# RZT2M register map
Vendor: Renesas Electronics Corporation; Series: RZT; File version: 1.20.01
CPU: other r0p0, little endian, MPU, no FPU, VTOR, 4 interrupt priority bits, 624 interrupts
Registers are 32-bit, read-write, reset 0x0 unless marked. A register's access mark holds for its fields unless they carry their own. Offsets are from the block's base; [hi:lo] are bit positions; {n}, {i} and the like mark numbered series.

## ETHSW (part 2 of 3) — Ethernet Switch
Base 0x80120000
0x5C8 TS_FIFO_READ_TIMESTAMP ro — 32-bit Timestamp Value Read from FIFO
  [31:0] TIMESTAMP — 32-bit timestamp value read from the FIFO
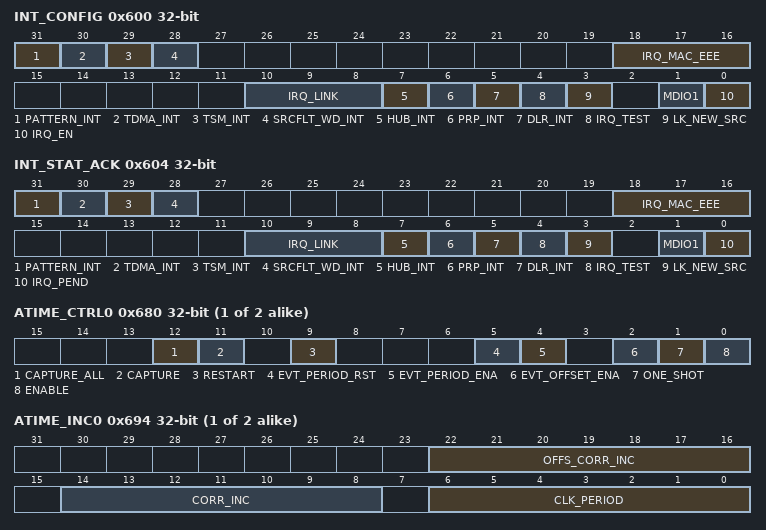
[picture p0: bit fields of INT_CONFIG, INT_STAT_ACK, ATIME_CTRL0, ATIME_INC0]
0x600 INT_CONFIG — Interrupt Enable Configuration Register
  [31] PATTERN_INT — Enable Interrupt for RX Pattern Matcher
  [30] TDMA_INT — Enable Interrupt for TDMA scheduler
  [29] TSM_INT — Enable Interrupt for TSM (Timer, Timestamping)
  [28] SRCFLT_WD_INT — MAC Address Source Filtering Watchdog
  [18:16] IRQ_MAC_EEE — Per Line Port MAC interrupt
  [10:8] IRQ_LINK — Per Line Port Phy Link Change Interrupt Enable
  [7] HUB_INT — Enable Interrupt for HUB
  [6] PRP_INT — Enable Interrupt for PRP
  [5] DLR_INT — Enable Interrupt for DLR
  [4] IRQ_TEST — When set, an interrupt is triggered immediately. Can be used to cause a software controlled interrupt for testing purposes.
  [3] LK_NEW_SRC — Enable Interrupt for New Source Address
  [1] MDIO1 — Enable Interrupt on Transaction Complete from MDIO Controller
  [0] IRQ_EN — Interrupt Global Enable
0x604 INT_STAT_ACK — Interrupt Status/ACK Register
  [31] PATTERN_INT ro — Interrupt Pending Status from RX Pattern Matcher Module
  [30] TDMA_INT ro — Interrupt Pending Status from TDMA Scheduler
  [29] TSM_INT ro — Interrupt Pending Interrupt Indication from TSM (Timestamping) module
  [28] SRCFLT_WD_INT — Interrupt Pending Status for MAC Source Filtering Watchdog
  [18:16] IRQ_MAC_EEE — Interrupt Pending Status per Line Port MAC Interrupt
  [10:8] IRQ_LINK — Interrupt Pending per Line Port Phy Link Change Interrupt
  [7] HUB_INT ro — Interrupt Pending Status from Hub Module
  [6] PRP_INT ro — Interrupt Pending Status from PRP Module
  [5] DLR_INT ro — Interrupt Pending Status from DLR Module
  [4] IRQ_TEST ro — Interrupt Status for IRQ_TEST
  [3] LK_NEW_SRC — Latched Interrupt Status for LK_NEW_SRC
  [1] MDIO1 — Latched Interrupt Status for MDIO1
  [0] IRQ_PEND ro — Interrupt Pending Status
{0x680+0x20*i} ATIME_CTRL{i} (i=0..1) — Timer {i} Control Register (n = 0, 1)
  [12] CAPTURE_ALL — Capture All Timers Value (Command Bit)
  [11] CAPTURE — Capture Time Value (Command Bit)
  [9] RESTART — Resets the Timer to Zero (Command Bit)
  [5] EVT_PERIOD_RST — Reset Timer on Periodical Event
  [4] EVT_PERIOD_ENA — Enable Periodical Event
  [2] EVT_OFFSET_ENA — Enable Offset Event
  [1] ONE_SHOT — Avoid timer wrap around. If set, the timer stops at maximum. An overflow interrupt (TSM_CONFIG.IRQ_ATIME_OVER) occurs (if enabled) when the maximum is reached.
  [0] ENABLE
{0x684+0x20*i} ATIME{i} (i=0..1) — Timer {i} Count Register (n = 0, 1)
  [31:0] TIMER_VAL — Timer Value
{0x688+0x20*i} ATIME_OFFSET{i} (i=0..1) — Timer {i} Offset Register (n = 0, 1)
  [31:0] OFFSET — Value used for performing offset corrections without changing the drift correction
{0x68C+0x20*i} ATIME_EVT_PERIOD{i} (i=0..1) reset 0x3B9ACA00 — Timer {i} Periodic Event Register (n = 0, 1)
  [31:0] PERIOD — Value for generating periodic events
{0x690+0x20*i} ATIME_CORR{i} (i=0..1) — Timer {i} Correction Period Register (n = 0, 1)
  [30:0] CORR_PERIOD — Correction Period
{0x694+0x20*i} ATIME_INC{i} (i=0..1) — Timer {i} Increment Register (n = 0, 1)
  [22:16] OFFS_CORR_INC — Offset Correction Increment Value
  [14:8] CORR_INC — Correction Increment Value
  [6:0] CLK_PERIOD — Clock Period of the Timestamping Clock (125 MHz) in nanoseconds
{0x698+0x20*i} ATIME_SEC{i} (i=0..1) — Timer {i} Seconds Time Register (n = 0, 1)
  [31:0] SEC_TIME — Seconds Time Value
{0x69C+0x20*i} ATIME_OFFS_CORR{i} (i=0..1) — Timer {i} Offset Correction Counter Register (n = 0, 1)
  [31:0] OFFS_CORR_CNT — Offset Correction Counter
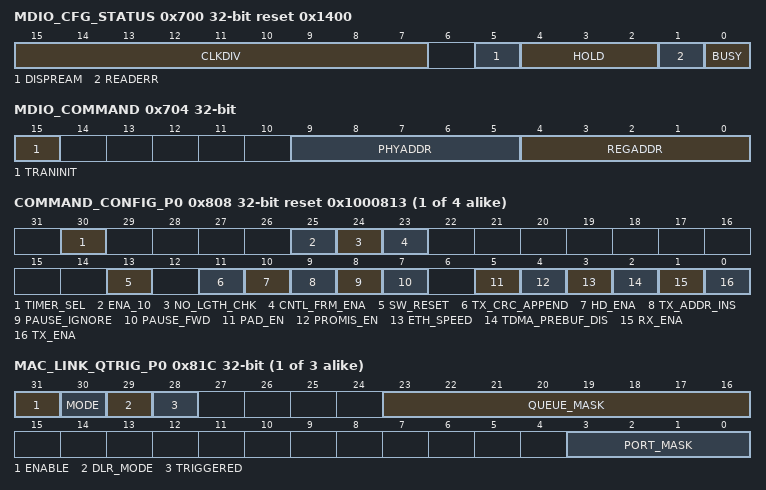
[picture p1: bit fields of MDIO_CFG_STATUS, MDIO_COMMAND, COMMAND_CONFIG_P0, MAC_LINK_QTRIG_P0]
0x700 MDIO_CFG_STATUS reset 0x1400 — MDIO Configuration and Status Register
  [15:7] CLKDIV — MDIO Clock Divisor
  [5] DISPREAM — Disable Preamble
    0=Enable Preamble; 1=Disable Preamble
  [4:2] HOLD — MDIO Hold Time Setting
    0=1 PCLKM clock cycle (default); 1=3 PCLKM clock cycles; 2=5 PCLKM clock cycles; 3=7 PCLKM clock cycles; 4=9 PCLKM clock cycles; 5=11 PCLKM clock cycles; 6=13 PCLKM clock cycles; 7=15 PCLKM clock cycles
  [1] READERR ro — MDIO Read Error
  [0] BUSY ro — MDIO Busy
0x704 MDIO_COMMAND — MDIO PHY Command Register
  [15] TRANINIT — If set to 1, a read transaction is initiated.
  [9:5] PHYADDR — PHY Address
  [4:0] REGADDR — Register Address
0x708 MDIO_DATA
  [15:0] MDIO_DATA
{0x800+0x400*i} REV_P{i} (i=0..3) ro reset 0x10002 (reset mask 0xFFFFFFFA) — Port {i} MAC Core Revision (n = 0 to 3)
  [31:0] REV — MAC Core Revision
{0x808+0x400*i} COMMAND_CONFIG_P{i} (i=0..3) reset 0x1000813 — Port {i} Command Configuration Register (n = 0 to 3)
  [30] TIMER_SEL — Selects the default timer to use for timestamping operations on transmit and on receive. The value is used when not overridden by the PTP auto-response function, pattern matchers or force forwarding information in a management tag.
    0=Use timer 0; 1=Use timer 1
  [25] ENA_10 — This bit has no effect except PHYSPEED bit of STATUS_Pn register.
  [24] NO_LGTH_CHK — Payload Length Check Disable
  [23] CNTL_FRM_ENA — MAC Control Frame Enable
  [13] SW_RESET — Self Clearing Reset Command Bit
  [11] TX_CRC_APPEND — Enable CRC Append on Transmit
  [10] HD_ENA — Enable auto full/half-duplex operation (set to 1) or full-duplex only (set to 0).
  [9] TX_ADDR_INS ro — Non writable bit, fixed to 0 always.
  [8] PAUSE_IGNORE — Ignore Pause Frame Quanta
  [7] PAUSE_FWD ro — Terminate/Forward Pause Frames
  [5] PAD_EN ro — Enable/Disable Frame Padding Remove on Receive
  [4] PROMIS_EN ro — Enable/Disable MAC Promiscuous Operation
  [3] ETH_SPEED — Operation Mode Definition
    0=10/100 Megabit mode; 1=1 Gigabit mode
  [2] TDMA_PREBUF_DIS — When set to 1, the MAC does not request a new frame from the IMC until the current frame is completed. This can cause the IPG between frames to be more than the value in TX_IPG_LENGTH.
  [1] RX_ENA — Enable/Disable MAC Receive Path
  [0] TX_ENA — Enable/Disable MAC Transmit Path
{0x80C+0x400*i} MAC_ADDR_0_P{i} (i=0..2) — Port {i} MAC Address Register 0 (n = 0 to 2)
  [31:0] MAC_ADDR — The first 4 bytes of the MAC address of the port. First byte is bits [7:0]. The MAC address is used on locally generated frames such as pause frames, peer-delay response.
{0x810+0x400*i} MAC_ADDR_1_P{i} (i=0..2) — Port {i} MAC Address Register 1 (n = 0 to 2)
  [15:0] MAC_ADDR — The last 2 bytes of the MAC address of the port. Bits [7:0] is the 5th byte and bits [15:8] is the 6th byte.
{0x814+0x400*i} FRM_LENGTH_P{i} (i=0..3) reset 0x5FE — Port {i} Maximum Frame Length Register (n = 0 to 3)
  [13:0] FRM_LENGTH — Maximum Frame Length
{0x818+0x400*i} PAUSE_QUANT_P{i} (i=0..3) ro reset 0xFFFF — Port {i} MAC Pause Quanta (n = 0 to 3)
  [15:0] PAUSE_QUANT — Pause Quanta
{0x81C+0x400*i} MAC_LINK_QTRIG_P{i} (i=0..2) — Port {i} Trigger Event Configuration Register (n = 0 to 2)
  [31] ENABLE — Write to 1 to enable the Link Queue Trigger feature. When the link status (phy_link) transitions from 1 -> 0, a trigger event is generated to the memory controller for the ports and queues indicated in PORT_MASK and QUEUE_MASK.
  [30] MODE — When set to 0, only a single Link_Status frame is generated. This is to prevent sending multiple frames due to link flapping.
  [29] DLR_MODE — When set to 0, the DLR state machine is ignored. When set to 1, the Link Queue Trigger occurs only if the DLR state machine is in the NORMAL or FAULT state.
  [28] TRIGGERED — When MODE is set to 1, TRIGGERED indicates whether a frame was transmitted. When MODE is set to 0, TRIGGERED is always 0. This flag clears when the register is written.
  [23:16] QUEUE_MASK — 1-bit per queue indicating from which queues a frame is transmitted from the ports indicated by PORT_MASK. A single frame is transmitted per indicated port in PORT_MASK among the queues indicated by QUEUE_MASK.
  [3:0] PORT_MASK — Per-port Bit Mask
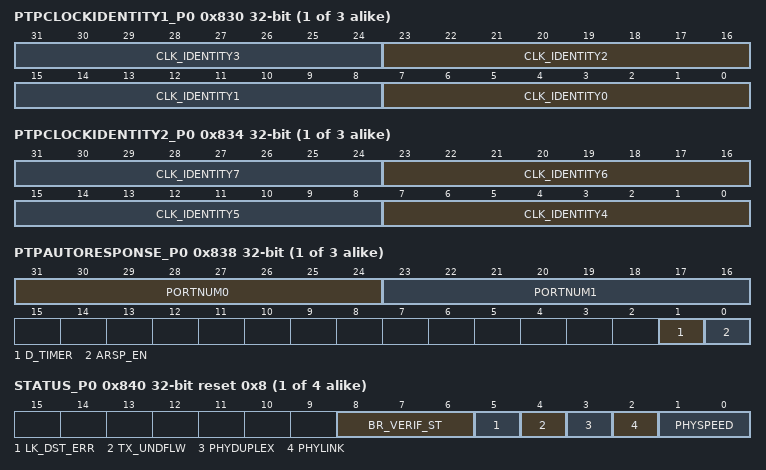
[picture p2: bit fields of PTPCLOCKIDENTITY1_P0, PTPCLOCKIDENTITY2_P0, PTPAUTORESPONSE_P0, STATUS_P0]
{0x830+0x400*i} PTPCLOCKIDENTITY1_P{i} (i=0..2) — Port {i} PTP Clock Identity 1 Register (n = 0 to 2)
  [8n+7:8n] CLK_IDENTITY{n} (n=0..3) — {n+20}, portIdentity.ClockIdentity[{n}]
{0x834+0x400*i} PTPCLOCKIDENTITY2_P{i} (i=0..2) — Port {i} PTP Clock Identity 2 Register (n = 0 to 2)
  [8n-25:8n-32] CLK_IDENTITY{n} (n=4..7) — {n+20}, portIdentity.ClockIdentity[{n}]
{0x838+0x400*i} PTPAUTORESPONSE_P{i} (i=0..2) — Port {i} PTP Auto Response Register (n = 0 to 2)
  [31:24] PORTNUM0 — 28, portIdentity.PortNumber[0] (msb)
  [23:16] PORTNUM1 — 29, portIdentity.PortNumber[1] (lsb)
  [1] D_TIMER — Default timer to use for auto-response generation
    0=Use timer 0; 1=Use timer 1
  [0] ARSP_EN — Auto Response Enable
{0x840+0x400*i} STATUS_P{i} (i=0..3) reset 0x8 (reset mask 0x1FC) — Port {i} Status Register
  [8:6] BR_VERIF_ST ro — Indicates the current status of the verification according to clause 30.14.1.2 of the 802.3br specification
    0=Unknown (during reset); 1=Initial (when preemption is disabled); 2=Verifying; 3=Succeeded; 4=Failed; 5=Disabled (if preempt verification is disabled)
  [5] LK_DST_ERR — Indicates that the L2 destination lookup process failed to complete in time before the next frame was received at the port. This should never occur under normal operation. The cause could be from IPG violations in the received frames.
  [4] TX_UNDFLW — Indicates that the transmit MAC underflow. This shall never occur during normal operation.
  [3] PHYDUPLEX ro — Duplex status from PHY interface
    0=half-duplex; 1=full-duplex
  [2] PHYLINK ro — Link status from PHY interface
    0=link down; 1=link up
  [1:0] PHYSPEED ro — Currently Active PHY Interface Speed
    0=10 Mbps; 1=100 Mbps; 2=1 Gbps
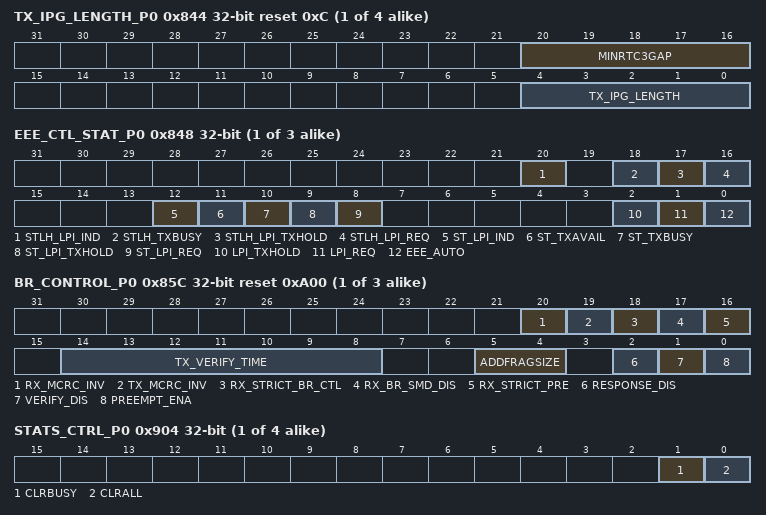
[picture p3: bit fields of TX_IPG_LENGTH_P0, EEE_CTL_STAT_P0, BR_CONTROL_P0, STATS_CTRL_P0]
{0x844+0x400*i} TX_IPG_LENGTH_P{i} (i=0..3) reset 0xC (reset mask 0x11001F) — Port {i} Transmit IPG Length Register (n = 0 to 3)
  [20:16] MINRTC3GAP
  [4:0] TX_IPG_LENGTH — Define transmit interpacket gap in octets. Allowed values are in the range of 8 to 31.
{0x848+0x400*i} EEE_CTL_STAT_P{i} (i=0..2) — Port {i} MAC EEE Functions Control and Status (n = 0 to 2)
  [20] STLH_LPI_IND ro — Status (latched high) of Received LPI (ST_LPI_IND)
  [18] STLH_TXBUSY ro — Status (latched high) if the MAC is/was Transmitting
  [17] STLH_LPI_TXHOLD ro — Status (latched high) of Internal LPI_TXHOLD to the MAC
  [16] STLH_LPI_REQ ro — Status (latched high) of Internal LPI_REQ to the MAC
  [12] ST_LPI_IND ro — Status (real time) of Received LPI
  [11] ST_TXAVAIL ro — Status (real time) if the MAC transmit FIFO has data available for transmission.
  [10] ST_TXBUSY ro — Status (real time) if the MAC is currently transmitting.
  [9] ST_LPI_TXHOLD ro — Status (real time) of Internal LPI_TXHOLD to the MAC
  [8] ST_LPI_REQ ro — Status (real time) of Internal LPI_REQ to the MAC
  [2] LPI_TXHOLD — MAC Transmission Hold
  [1] LPI_REQ — Request LPI Transmission when MAC Becomes Idle
  [0] EEE_AUTO — EEE Automatic Mode of Operation
{0x84C+0x400*i} EEE_IDLE_TIME_P{i} (i=0..2) — Port {i} EEE Idle Time Register (n = 0 to 2)
  [31:0] EEE_IDLE_TIME — Time (-1) the transmitter must be idle before transmission of LPI begins. A 32-bit value in steps of 32 switch operating clock cycles. A value of 0 disables the timer. The value must be set to 1 less count.
{0x850+0x400*i} EEE_TWSYS_TIME_P{i} (i=0..2) — Port {i} EEE Wake Up Time Register (n = 0 to 2)
  [31:0] EEE_WKUP_TIME — Time (-1) after PHY wakeup until the MAC is allowed to begin transmitting the first frame again. A 32-bit value in steps of switch operating clock cycles. A value of 0 disables the timer. The value must be set to 1 less count.
{0x854+0x400*i} IDLE_SLOPE_P{i} (i=0..3) — Port {i} MAC Traffic Shaper Bandwidth Control
  [10:0] IDLE_SLOPE — Traffic Shaper Bandwidth Control
{0x858+0x400*i} CT_DELAY_P{i} (i=0..2) — Port {i} Cut-Through Delay Indication Register
  [8:0] CT_DELAY — Delay Value in 400 ns / 40 ns / 8 ns increments (frequency of the MII PHY interface)
{0x85C+0x400*i} BR_CONTROL_P{i} (i=0..2) reset 0xA00 — Port {i} 802.3br Frame Configuration Register
  [20] RX_MCRC_INV — When set to 1, the 32-bit XOR mask used to calculate the mCRC for received frames is inverted. This bit must always be written to 0 and only used for debugging.
  [19] TX_MCRC_INV — When set to 1, the 32-bit XOR mask used to calculate the mCRC for transmitted frames is inverted. This bit must always be written to 0 and only used for debugging.
  [18] RX_STRICT_BR_CTL — When set to 1, strict checking of VERIFY and RESPONSE frames is enabled. When set to 1, the frame contents and frame length checks are also performed on these frames. The mCRC is always checked regardless of the value of this register. This bit must be set to 0 to be compliant with the functionality described in IEEE 802.3br.
  [17] RX_BR_SMD_DIS — When set to 1, the receiver does not decode the 802.3br SMDs and assumes all frames are express frames. This bit must be set to 0 for correct operation with 802.3br, and can be set to 1 when 802.3br is not enabled to avoid false detection of SMDs.
  [16] RX_STRICT_PRE — When set to 1, the preamble is checked so all bytes except the SFD are 0x55. When set to 0, only the last 2 bytes of the preamble are checked (SFD/SMD and FRAG_COUNT). It is recommended to set this bit to 1 to comply with the 802.3br specification. This bit must be set to 0 if only non-802.3br traffic is expected (for example, normal Ethernet traffic) and if custom preamble is used.
  [14:8] TX_VERIFY_TIME — Preemption verification timeout in milliseconds.
  [5:4] ADDFRAGSIZE — Minimum fragment size in increments of 64 bytes.
  [2] RESPONSE_DIS — When set to 1 prevents the MAC from responding to "verify" frames.
  [1] VERIFY_DIS — When set to 1, disables the verify process required for preemption operation.
  [0] PREEMPT_ENA — When set to 1, enables 802.3br Frame Preemption.
{0x868+0x400*i} AFRAMESTRANSMITTEDOK_P{i} (i=0..3) ro — Port {i} MAC Transmitted Valid Frame Count Register (n = 0 to 3)
  [31:0] TXVALIDCOUNT — PORT n, this field indicates the number of MAC Valid Transmitted, including pause.
{0x86C+0x400*i} AFRAMESRECEIVEDOK_P{i} (i=0..3) ro — Port {i} MAC Received Valid Frame Count Register (n = 0 to 3)
  [31:0] RXVALIDCOUNT — PORT n, this field indicates the number of MAC Valid Received, including pause.
{0x870+0x400*i} AFRAMECHECKSEQUENCEERRORS_P{i} (i=0..3) ro — Port {i} MAC FCS Error Frame Count Register (n = 0 to 3)
  [31:0] FCSERRCOUNT — PORT n, this field indicates the number of MAC Valid Length but CRC error.
{0x874+0x400*i} AALIGNMENTERRORS_P{i} (i=0..3) ro — Port {i} MAC Alignment Error Frame Count Register (n = 0 to 3)
  [31:0] ALGNERRCOUNT — PORT n, this field indicates the number of MAC Odd Number of Nibbles (MII) Received.
{0x878+0x400*i} AOCTETSTRANSMITTEDOK_P{i} (i=0..3) ro — Port {i} MAC Transmitted Valid Frame Octets Register (n = 0 to 3)
  [31:0] TXVALIDOCTETS — PORT n, this field indicates the octets (the payload only) of MAC Valid Transmitted.
{0x87C+0x400*i} AOCTETSRECEIVEDOK_P{i} (i=0..3) ro — Port {i} MAC Received Valid Frame Octets Register (n = 0 to 3)
  [31:0] RXVALIDOCTETS — PORT n, this field indicates the octets (the payload only) of MAC Valid Received.
{0x880+0x400*i} ATXPAUSEMACCTRLFRAMES_P{i} (i=0..3) ro — Port {i} MAC Transmitted Pause Frame Count Register (n = 0 to 3)
  [31:0] TXPAUSECOUNT — PORT n, this field indicates the number of MAC Valid Pause Transmitted.
{0x884+0x400*i} ARXPAUSEMACCTRLFRAMES_P{i} (i=0..3) ro — Port {i} MAC Received Pause Frame Count Register (n = 0 to 3)
  [31:0] RXPAUSECOUNT — PORT n, this field indicates the number of MAC Valid Pause Received.
{0x888+0x400*i} IFINERRORS_P{i} (i=0..3) ro — Port {i} MAC Input Error Count Register (n = 0 to 3)
  [31:0] INERRCOUNT — PORT n, this field indicates the number of MAC Any Error During Reception such as CRC, Length, PHY Error, RX FIFO Overflow.
{0x88C+0x400*i} IFOUTERRORS_P{i} (i=0..3) ro — Port {i} MAC Output Error Count Register (n = 0 to 3)
  [31:0] OUTERRCOUNT — PORT n, this field indicates the number of MAC Frame Transmitted with PHY error.
{0x890+0x400*i} IFINUCASTPKTS_P{i} (i=0..3) ro — Port {i} MAC Received Unicast Frame Count Register (n = 0 to 3)
  [31:0] RXUCASTCOUNT — PORT n, this field indicates the number of MAC Unicast Frame Valid Received.
{0x894+0x400*i} IFINMULTICASTPKTS_P{i} (i=0..3) ro — Port {i} MAC Received Multicast Frame Count Register (n = 0 to 3)
  [31:0] RXMCASTCOUNT — PORT n, this field indicates the number of MAC Multicast Frame Valid Received.
{0x898+0x400*i} IFINBROADCASTPKTS_P{i} (i=0..3) ro — Port {i} MAC Received Broadcast Frame Count Register (n = 0 to 3)
  [31:0] RXBCASTCOUNT — PORT n, this field indicates the number of MAC Broadcast Frame Valid Received.
{0x89C+0x400*i} IFOUTDISCARDS_P{i} (i=0..3) ro — Port {i} MAC Discarded Outbound Frame Count Register (n = 0 to 3)
  [31:0] DISCOBCOUNT — Not Applicable
{0x8A0+0x400*i} IFOUTUCASTPKTS_P{i} (i=0..3) ro — Port {i} MAC Transmitted Unicast Frame Count Register (n = 0 to 3)
  [31:0] TXUCASTCOUNT — PORT n, this field indicates the number of MAC Unicast Frame Valid Transmitted.
{0x8A4+0x400*i} IFOUTMULTICASTPKTS_P{i} (i=0..3) ro — Port {i} MAC Transmitted Multicast Frame Count Register (n = 0 to 3)
  [31:0] TXMCASTCOUNT — PORT n, this field indicates the number of MAC Multicast Frame Valid Transmitted.
{0x8A8+0x400*i} IFOUTBROADCASTPKTS_P{i} (i=0..3) ro — Port {i} MAC Transmitted Broadcast Frame Count Register (n = 0 to 3)
  [31:0] TXBCASTCOUNT — PORT n, this field indicates the number of MAC Broadcast Frame Valid Transmitted.
{0x8AC+0x400*i} ETHERSTATSDROPEVENTS_P{i} (i=0..3) ro — Port {i} MAC Dropped Frame Count Register (n = 0 to 3)
  [31:0] DROPCOUNT — PORT n, this field indicates the number of MAC RX FIFO Full at frame start.
{0x8B0+0x400*i} ETHERSTATSOCTETS_P{i} (i=0..3) ro — Port {i} MAC All Frame Octets Register (n = 0 to 3)
  [31:0] ALLOCTETS
{0x8B4+0x400*i} ETHERSTATSPKTS_P{i} (i=0..3) ro — Port {i} MAC All Frame Count Register (n = 0 to 3)
  [31:0] ALLCOUNT
{0x8B8+0x400*i} ETHERSTATSUNDERSIZEPKTS_P{i} (i=0..3) ro — Port {i} MAC Too Short Frame Count Register (n = 0 to 3)
  [31:0] TOOSHRTCOUNT — PORT n, this field indicates the number of MAC too Short, Good CRC.
{0x8BC+0x400*i} ETHERSTATSOVERSIZEPKTS_P{i} (i=0..3) ro — Port {i} MAC Too Long Frame Count Register (n = 0 to 3)
  [31:0] TOOLONGCOUNT — PORT n, this field indicates the number of MAC too Long, Good CRC.
{0x8C0+0x400*i} ETHERSTATSPKTS64OCTETS_P{i} (i=0..3) ro — Port {i} MAC 64 Octets Frame Count Register (n = 0 to 3)
  [31:0] OCTCNT64 — PORT n, this field indicates the number of MAC All Frames, Good and Bad (Packet Size: 64 bytes).
{0x8C4+0x400*i} ETHERSTATSPKTS65TO127OCTETS_P{i} (i=0..3) ro — Port {i} MAC 65 to 127 Octets Frame Count Register (n = 0 to 3)
  [31:0] OCTCNT65T127 — PORT n, this field indicates the number of MAC All Frames, Good and Bad (Packet Size: 65 to 127 bytes).
{0x8C8+0x400*i} ETHERSTATSPKTS128TO255OCTETS_P{i} (i=0..3) ro — Port {i} MAC 128 to 255 Octets Frame Count Register (n = 0 to 3)
  [31:0] OCTCNT128T255 — PORT n, this field indicates the number of MAC All Frames, Good and Bad (Packet Size: 128 to 255 bytes).
{0x8CC+0x400*i} ETHERSTATSPKTS256TO511OCTETS_P{i} (i=0..3) ro — Port {i} MAC 256 to 511 Octets Frame Count Register (n = 0 to 3)
  [31:0] OCTCNT256T511 — PORT n, this field indicates the number of MAC All Frames, Good and Bad (Packet Size: 256 to 511 bytes).
{0x8D0+0x400*i} ETHERSTATSPKTS512TO1023OCTETS_P{i} (i=0..3) ro — Port {i} MAC 512 to 1023 Octets Frame Count Register (n = 0 to 3)
  [31:0] OCTCNT512T1023 — PORT n, this field indicates the number of MAC All Frames, Good and Bad (Packet Size: 512 to 1023 bytes).
{0x8D4+0x400*i} ETHERSTATSPKTS1024TO1518OCTETS_P{i} (i=0..3) ro — Port {i} MAC 1024 to 1518 Octets Frame Count Register (n = 0 to 3)
  [31:0] OCTCNT1024T1518 — PORT n, this field indicates the number of MAC All Frames, Good and Bad (Packet Size: 1024 to 1518 bytes).
{0x8D8+0x400*i} ETHERSTATSPKTS1519TOXOCTETS_P{i} (i=0..3) ro — Port {i} MAC Over 1519 Octets Frame Count Register (n = 0 to 3)
  [31:0] OCTCNT1519TX — PORT n, this field indicates the number of MAC all Frames, Good and Bad (Packet Size: over 1519 bytes).
{0x8DC+0x400*i} ETHERSTATSJABBERS_P{i} (i=0..3) ro — Port {i} MAC Jabbers Frame Count Register (n = 0 to 3)
  [31:0] JABBERCOUNT — PORT n, this field indicates the number of MAC too Long, Bad CRC.
{0x8E0+0x400*i} ETHERSTATSFRAGMENTS_P{i} (i=0..3) ro — Port {i} MAC Fragment Frame Count Register (n = 0 to 3)
  [31:0] FRAGCOUNT — PORT n, this field indicates the number of MAC too Short, Bad CRC.
{0x8E8+0x400*i} VLANRECEIVEDOK_P{i} (i=0..3) ro — Port {i} MAC Received VLAN Tagged Frame Count Register (n = 0 to 3)
  [31:0] RXVLANTAGCNT — PORT n, this field indicates the number of Good Frames with VLAN Tag Received.
{0x8F4+0x400*i} VLANTRANSMITTEDOK_P{i} (i=0..3) ro — Port {i} MAC Transmitted VLAN Tagged Frame Count Register (n = 0 to 3)
  [31:0] TXVLANTAGCNT — PORT n, this field indicates the number of Good Frames with VLAN Tag Transmitted.
{0x8F8+0x400*i} FRAMESRETRANSMITTED_P{i} (i=0..3) ro — Port {i} MAC Retransmitted Frame Count Register (n = 0 to 3)
  [31:0] RETXCOUNT — PORT n, this field indicates the number of Transmitted Frames that experienced a collision and were retransmitted.
{0x900+0x400*i} STATS_HIWORD_P{i} (i=0..3) ro — Port {i} MAC Statistics Counter High Word Register (n = 0 to 3)
  [31:0] STATS_HIWORD — The latched upper 32-bit of the 64 bits MAC Statistics Counter Last Read
{0x904+0x400*i} STATS_CTRL_P{i} (i=0..3) — Port {i} MAC Statistics Control Register (n = 0 to 3)
  [1] CLRBUSY ro — Clear in Progress Indication
  [0] CLRALL — Self Clearing Counter Initialize Command
{0x908+0x400*i} STATS_CLEAR_VALUELO_P{i} (i=0..3) — Port {i} MAC Statistics Clear Value Lower Register (n = 0 to 3)
  [31:0] STATS_CLEAR_VALUELO — PORT n, lower 32-bit of 64 bits value loaded into all counters when clearing all counters with STATS_CTRL_Pn.CLRALL command for test purposes. These bits should be set to 0 normally.
{0x90C+0x400*i} STATS_CLEAR_VALUEHI_P{i} (i=0..3) — Port {i} MAC Statistics Clear Value Higher Register (n = 0 to 3)
  [31:0] STATS_CLEAR_VALUEHI — PORT n, upper 32-bit of 64 bits value loaded into all counters when clearing all counters with STATS_CTRL_Pn.CLRALL command for test purposes. These bits should be set to 0 normally.
{0x910+0x400*i} ADEFERRED_P{i} (i=0..3) ro — Port {i} MAC Deferred Count Register (n = 0 to 3)
  [31:0] DEFERCOUNT — PORT n, this field indicates the number of Frame Transmitted without collision but was deferred at begin.
{0x914+0x400*i} AMULTIPLECOLLISIONS_P{i} (i=0..3) ro — Port {i} MAC Multiple Collision Count Register (n = 0 to 3)
  [31:0] COUNTAFTMLTCOLL — PORT n, this field indicates the number of Good Frame Transmit after multiple collisions.
{0x918+0x400*i} ASINGLECOLLISIONS_P{i} (i=0..3) ro — Port {i} MAC Single Collision Count Register (n = 0 to 3)
  [31:0] COUNTAFTSNGLCOLL — PORT n, this field indicates the number of Good Frame Transmit after single collision.
{0x91C+0x400*i} ALATECOLLISIONS_P{i} (i=0..3) ro — Port {i} MAC Late Collision Count Register (n = 0 to 3)
  [31:0] LATECOLLCOUNT — PORT n, this field indicates the number of too Late Collision. Frame was aborted and not retransmitted.
{0x920+0x400*i} AEXCESSIVECOLLISIONS_P{i} (i=0..3) ro — Port {i} MAC Excessive Collision Count Register (n = 0 to 3)
  [31:0] EXCCOLLCOUNT — PORT n, this field indicates the number of Frames Discarded due to 16 consecutive collisions.
{0x924+0x400*i} ACARRIERSENSEERRORS_P{i} (i=0..3) ro — Port {i} MAC Carrier Sense Error Count Register (n = 0 to 3)
  [31:0] CSERRCOUNT — PORT n, increments during Transmission without Collisions the PHY Carrier Sense Signal (RX_CRS) dropped or never asserted.
0x3404 STATN_STATUS ro — Statistics Status Register
  [0] BUSY — Statistics module is busy
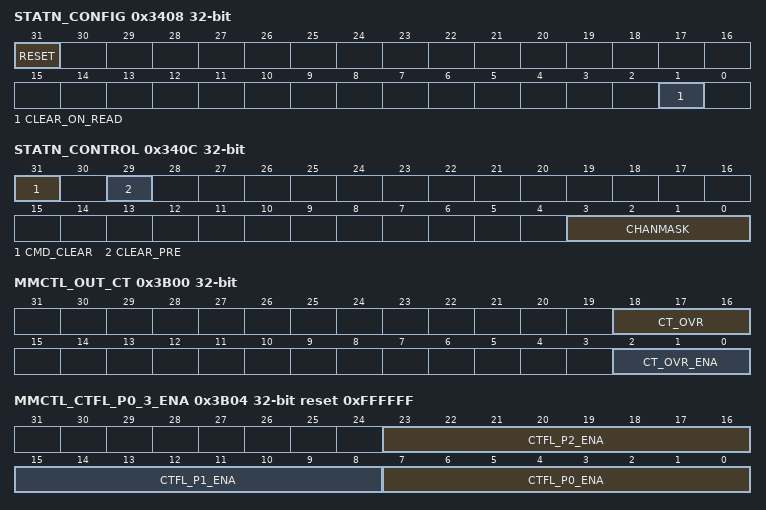
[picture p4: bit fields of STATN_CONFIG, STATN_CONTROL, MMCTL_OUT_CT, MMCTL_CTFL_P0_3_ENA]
0x3408 STATN_CONFIG — Statistics Configure Register
  [31] RESET — When set to 1, all internal functions are aborted and return to a stable state (flushes prescalers). It also triggers a clear of all counter memory (all ports are cleared) by setting STATN_CONTROL.CMD_CLEAR with all mask bits. Capture memory is not reset.
  [1] CLEAR_ON_READ — When set to 1, a read to a counter resets it to 0. When set to 0 (default), counters are not affected by read.
0x340C STATN_CONTROL — Statistics Control Register
  [31] CMD_CLEAR — Clear Channel Counters Command
  [29] CLEAR_PRE — Clear the internal pre-scaler counters of ports when a clear occurs. This bit can be used together with the CMD_CLEAR command to clear the internal pre-scaler counters of the ports.
  [3:0] CHANMASK — One bit per port. Bit 0 = port 0, bit 1 = port 1, and so on.
0x3410 STATN_CLEARVALUE_LO — Statistics Clear Value Lower Register
  [31:0] STATN_CLEARVALUE_LO — 32-bit value written into statistics memory when a clear command (STATN_CONTROL.CMD_CLEAR) is triggered (see ), or when a clear-after-read is used.
{0x3468+0x48*i} ODISC{i} (i=0..3) ro — Port {i} Discarded Outgoing Frame Count Register
  [31:0] ODISC — Port n outgoing frames discarded due to output queue congestion.
{0x346C+0x48*i} IDISC_VLAN{i} (i=0..3) ro — Port {i} Discarded Incoming VLAN Tagged Frame Count Register
  [31:0] IDISC_VLAN — Port n incoming frames discarded due to mismatching or missing VLAN ID while VLAN verification was enabled.
{0x3470+0x48*i} IDISC_UNTAGGED{i} (i=0..3) ro — Port {i} Discarded Incoming VLAN Untagged Frame Count Register
  [31:0] IDISC_UNTAGGED — Port n incoming frames discarded due to missing VLAN tag.
{0x3474+0x48*i} IDISC_BLOCKED{i} (i=0..3) ro — Port {i} Discarded Incoming Blocked Frame Count Register
  [31:0] IDISC_BLOCKED — Port n incoming frames discarded (after learning) as the port is configured in blocking mode.
{0x3478+0x48*i} IDISC_ANY{i} (i=0..3) ro — Port {i} Discarded Any Frame Count Register (n = 0 to 3)
  [31:0] IDISC_ANY — Port n total incoming frames discarded. This includes IDISC_VLAN, IDSIC_UNTAGGED, IDISC_SRCFLT, and IDISC_BLOCKED.
{0x347C+0x48*i} IDISC_SRCFLT{i} (i=0..2) ro — Port {i} Discarded Address Source Count Register
  [31:0] IDISC_SRCFLT — Port n counts the number of incoming frames discarded due to the MAC address source filter.
{0x3480+0x48*i} TX_HOLD_REQ_CNT{i} (i=0..2) ro — Port {i} TX Hold Request Count Register
  [31:0] TX_HOLD_REQ_CNT
{0x3484+0x48*i} TX_FRAG_CNT{i} (i=0..2) ro — Port {i} TX for Preemption Count Register
  [31:0] TX_FRAG_CNT — Port n increments when an additional mPacket is transmitted due to preemption.
{0x3488+0x48*i} RX_FRAG_CNT{i} (i=0..2) ro — Port {i} RX Continuation Count Register
  [31:0] RX_FRAG_CNT — Port n increments for every continuation mPacket received.
{0x348C+0x48*i} RX_ASSY_OK_CNT{i} (i=0..2) ro — Port {i} RX Preempted Frame Success Count Register
  [31:0] RX_ASSY_OK_CNT — Port n increments when a preempted frame is successfully assembled.
{0x3490+0x48*i} RX_ASSY_ERR_CNT{i} (i=0..2) ro — Port {i} RX Preempted Frame Incorrect Count Register
  [15:0] RX_ASSY_ERR_CNT — Port n increments when a preempted frame is incorrectly assembled.
{0x3494+0x48*i} RX_SMD_ERR_CNT{i} (i=0..2) ro — Port {i} RX SMD Frame Count Register
  [15:0] RX_SMD_ERR_CNT — Port n increments when a frame with an SMD-Cx is received and no assembly is in progress.
{0x3498+0x48*i} TX_VERIFY_OK_CNT{i} (i=0..2) ro — Port {i} TX VERIFY Frame Count Register
  [7:0] TX_VERIFY_OK_CNT — Port n increments for every VERIFY frame transmitted.
{0x349C+0x48*i} TX_RESPONSE_OK_CNT{i} (i=0..2) ro — Port {i} TX RESPONSE Frame Count Register
  [7:0] TX_RESPONSE_OK_CNT — Port n increments for every RESPONSE frame transmitted.
{0x34A0+0x48*i} RX_VERIFY_OK_CNT{i} (i=0..2) ro — Port {i} RX VERIFY Frame Count Register
  [7:0] RX_VERIFY_OK_CNT — Port n increments for every valid VERIFY frame received.
{0x34A4+0x48*i} RX_RESPONSE_OK_CNT{i} (i=0..2) ro — Port {i} RX RESPONSE Frame Count Register
  [7:0] RX_RESPONSE_OK_CNT — Port n increments for every valid RESPONSE frame received.
{0x34A8+0x48*i} RX_VERIFY_BAD_CNT{i} (i=0..2) ro — Port {i} RX Error VERIFY Frame Count Register
  [7:0] RX_VERIFY_BAD_CNT — Port n increments for every errored VERIFY frame received.
{0x34AC+0x48*i} RX_RESPONSE_BAD_CNT{i} (i=0..2) ro — Port {i} RX Error RESPONSE Frame Count Register
  [7:0] RX_RESPONSE_BAD_CNT — Port n increments for every errored RESPONSE frame received.
0x3B00 MMCTL_OUT_CT — Cut-Through Register
  [18:16] CT_OVR — 1 bit per-port value to set the Cut Through behavior of the output ports. When set to 0, all frames are sent as Store & Forward (SF) frames. When set to 1, frames with the CT flag set in the frame context are started as soon as the frame context information is available.
  [2:0] CT_OVR_ENA — Per-port bit mask to enable overriding the Cut-Through (CT) behavior of the output ports with CT_OVR. When set to 0, the frames are transmitted CT if the CT flag of the frame context is set.
0x3B04 MMCTL_CTFL_P0_3_ENA reset 0xFFFFFF — Cut-Through Frame Length Enable Register
  [23:16] CTFL_P2_ENA — Port 2 bit mask of n bits, where n is the number of queues per port indicating whether the CTFL is used for Cut-Through (CT) frames. When set to 1, a CT frame requires a CTFL entry to be written as a CT frame in the output memory.
  [15:8] CTFL_P1_ENA — Port 1 bit mask of n bits, where n is the number of queues per port indicating whether the CTFL is used for Cut-Through (CT) frames. When set to 1, a CT frame requires a CTFL entry to be written as a CT frame in the output memory.
  [7:0] CTFL_P0_ENA — Port 0 bit mask of n bits, where n is the number of queues per port indicating whether the CTFL is used for Cut-Through (CT) frames. When set to 1, a CT frame requires a CTFL entry to be written as a CT frame in the output memory.
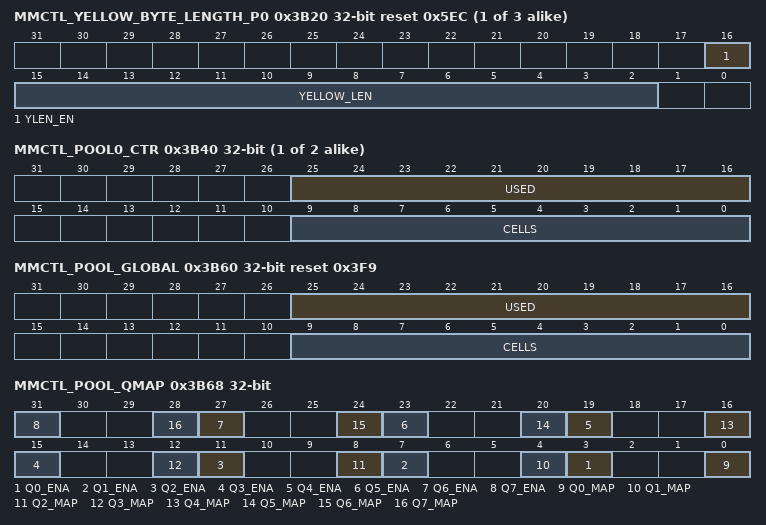
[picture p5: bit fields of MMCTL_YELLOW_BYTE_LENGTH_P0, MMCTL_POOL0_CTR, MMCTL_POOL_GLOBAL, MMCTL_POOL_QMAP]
{0x3B20+4i} MMCTL_YELLOW_BYTE_LENGTH_P{i} (i=0..2) reset 0x5EC — Port {i} Yellow Period Byte Length Register
  [16] YLEN_EN — When set to 1, enables transmission when OUT_CT_ENA is low only if the frame length is less than YELLOW_LEN. If cleared, YELLOW_LEN is ignored and frames are always transmitted in SF mode when OUT_CT_ENA is 0.
  [15:2] YELLOW_LEN — Length in bytes of the YELLOW period for port n. Determines whether a frame can be transmitted before the YELLOW period expires. The value is programmed in increments of 4 bytes excluding the MAC overhead (IPG, Preamble and FCS if appended) of the frame.
{0x3B40+4i} MMCTL_POOL{i}_CTR (i=0..1) — Memory Pool Counter (n = 0 to 1)
  [25:16] USED ro — Reports the current available number of used cells for this memory pool. The used number of free cells can be calculated as CELLS - USED.
  [9:0] CELLS — Memory pool configuration for pool n. Configures, in cells, the size of each memory pool.
0x3B60 MMCTL_POOL_GLOBAL reset 0x3F9 — Memory Pool Configuration Register
  [25:16] USED ro — Reports the current number of used cells for the global shared pool. The used number of free cells can be calculated as CELLS - USED.
  [9:0] CELLS — Memory pool configuration for the global pool. Configures, in cells, the size of the global shared pool.
0x3B64 MMCTL_POOL_STATUS ro — Memory Pool Status Register
  [7:0] QUEUE_FULL — Per-queue pool full indication. Indicates for each queue whether all the blocks in the corresponding pool and global pool are allocated.
0x3B68 MMCTL_POOL_QMAP — Queue MAP Register
  [4n+3] Q{n}_ENA (n=0..7) — Queue {n} Memory Pool Enabled
    0=The queue only uses cells from the global pool; 1=The queue uses the pool programmed in Q{n}_MAP
  [4n] Q{n}_MAP (n=0..7) — Queue {n} Memory Pool
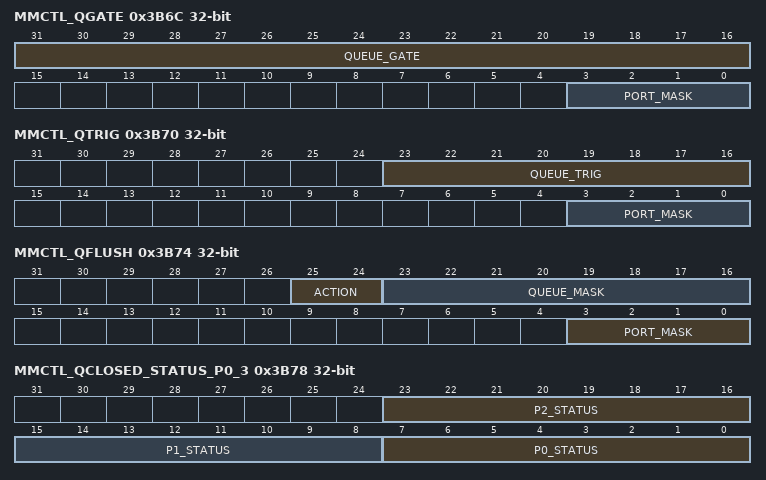
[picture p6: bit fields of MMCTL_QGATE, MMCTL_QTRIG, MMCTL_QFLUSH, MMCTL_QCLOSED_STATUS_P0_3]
0x3B6C MMCTL_QGATE wo — Queue Gate State Register
  [31:16] QUEUE_GATE — 2-bit per queue indicating the action to be performed on each queue of the ports indicated by PORT_MASK.
    0=Hold state, does not change the queue gate state; 1=Toggle state, toggles the gate state; 2=Gate queue, closes the queue; 3=Open queue, enables the queue
  [3:0] PORT_MASK — Per-port bit mask. When set to 1 for a port, the queue gate state is changed for that port as indicated by QUEUE_GATE.
0x3B70 MMCTL_QTRIG wo — Queue Trigger Register
  [23:16] QUEUE_TRIG — 1-bit per queue indicating from which queues a frame is to be transmitted from the ports indicated by PORT_MASK. When set to 1, a single frame is transmitted per indicated port in PORT_MASK among the queues indicated by QUEUE_TRIG.
  [3:0] PORT_MASK — Per-port bit mask. When set to 1 for a port, a frame is triggered from the closed queues indicated by QUEUE_TRIG.
0x3B74 MMCTL_QFLUSH wo — Flush Event Select Register
  [25:24] ACTION — Selects the flush state for the queues indicated by QUEUE_MASK in the ports indicated by PORT_MASK. Possible actions are:
    0=Disable flush; 1=Flush when queue is closed, discarding any new frames; 2=Flush on queue close until empty, then stops flushing; 3=TRIGGER flush until empty, then return to current flush mode
  [23:16] QUEUE_MASK — 1 bit per queue indicating for which queues of the ports indicated by PORT_MASK the flush state is changed as indicated in ACTION.
  [3:0] PORT_MASK — Per-port bit mask. When set to 1 for a port, the queue flush status is changed for that port for the queues indicated in QUEUE_MASK.
0x3B78 MMCTL_QCLOSED_STATUS_P0_3 ro — Queue Closed Status Register
  [23:16] P2_STATUS — Per-queue closed status of Port 2 (1-bit per queue). A 0 indicates that the queue is open (enabled), and a 1 indicates that the queue is closed (disabled).
  [15:8] P1_STATUS — Per-queue closed status of Port 1 (1-bit per queue). A 0 indicates that the queue is open (enabled), and a 1 indicates that the queue is closed (disabled).
  [7:0] P0_STATUS — Per-queue closed status of Port 0 (1-bit per queue). A 0 indicates that the queue is open (enabled), and a 1 indicates that the queue is closed (disabled).
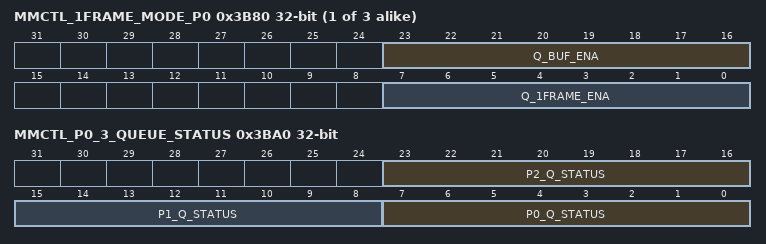
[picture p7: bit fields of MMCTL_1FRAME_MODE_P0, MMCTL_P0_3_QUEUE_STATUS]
{0x3B80+4i} MMCTL_1FRAME_MODE_P{i} (i=0..2) — Port {i} 1-Frame Mode Configuration Register
  [23:16] Q_BUF_ENA — 1 bit per queue. Setting a bit to 1 enables the buffer mode behavior for that queue for port n. This mode requires also that Q_1FRAME_ENA is set to 1.
  [7:0] Q_1FRAME_ENA — 1 bit per queue. Setting a bit to 1 enables the 1-frame mode for that queue for port n. In this mode, only one frame is allowed in the queue. If a new frame is received, the old frame is discarded.
0x3BA0 MMCTL_P0_3_QUEUE_STATUS ro — Queue Status Indicator
  [all] fields
    0=Queue is empty; 1=Queued frames
  [23:16] P2_Q_STATUS — Port 2 Per-Queue Bit Indication
  [15:8] P1_Q_STATUS — Port 1 Per-Queue Bit Indication
  [7:0] P0_Q_STATUS — Port 0 Per-Queue Bit Indication

## Notices in the file
Copyright (c) 2020 - 2025 Renesas Electronics Corporation and/or its affiliates
SPDX-License-Identifier: BSD-3-Clause
